# GPU0_KLIOMP1_HL_MMRS register map
Vendor: Texas Instruments
Peripheral module from a debugger description file (folder am65x).
Registers are 32-bit, access per field, reset values left out (the file's numbers can be read two ways) unless marked. A register's access mark holds for its fields unless they carry their own. Offsets are as the file gives them; lines under a group give offsets from that group; [hi:lo] are bit positions; {n}, {i} and the like mark numbered series; 'fields as' and 'values as' point back to an identical list; <NAME> marks a mode.

## GPU0_KLIOMP1_HL_MMRS
0x00 GPU_REVISION ro — See IPG spec for more details.
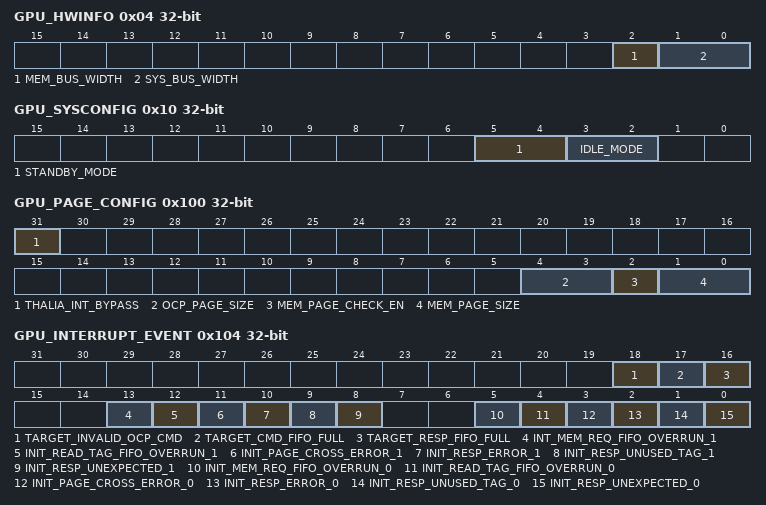
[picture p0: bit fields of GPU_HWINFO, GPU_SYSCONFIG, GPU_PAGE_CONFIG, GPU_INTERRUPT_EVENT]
0x04 GPU_HWINFO ro
  [2] MEM_BUS_WIDTH — Memory bus width Read 0h = 64 bits Read 1h = 128 bits
  [1:0] SYS_BUS_WIDTH — System bus width
0x10 GPU_SYSCONFIG
  [5:4] STANDBY_MODE rw — Clock standby mode:
  [3:2] IDLE_MODE rw — Clock idle mode:
0x24 GPU_IRQSTATUS_RAW_0
  [0] INIT_MINTERRUPT_RAW rw — Interrupt 0 raw event:
0x28 GPU_IRQSTATUS_RAW_1
  [0] TARGET_SINTERRUPT_RAW rw — Interrupt 1 raw event:
0x2C GPU_IRQSTATUS_RAW_2
  [0] THALIA_IRQ_RAW rw — Interrupt 1 raw event:
0x30 GPU_IRQSTATUS_0
  [0] INIT_MINTERRUPT_STATUS rw — Interrupt 0 raw event:
0x34 GPU_IRQSTATUS_1
  [0] TARGET_SINTERRUPT_STATUS rw — Interrupt 0 raw event:
0x38 GPU_IRQSTATUS_2
  [0] THALIA_IRQ_STATUS rw — Interrupt 0 raw event:
0x3C GPU_IRQENABLE_SET_0
  [0] INIT_MINTERRUPT_ENABLE rw — To enable interrupt:
0x40 GPU_IRQENABLE_SET_1
  [0] TARGET_SINTERRUPT_ENABLE rw — To enable interrupt:
0x44 GPU_IRQENABLE_SET_2
  [0] THALIA_IRQ_ENABLE rw — To enable interrupt:
0x48 GPU_IRQENABLE_CLR_0
  [0] INIT_MINTERRUPT_DISABLE rw — To disable interrupt:
0x4C GPU_IRQENABLE_CLR_1
  [0] TARGET_SINTERRUPT_DISABLE rw — To disable interrupt:
0x50 GPU_IRQENABLE_CLR_2
  [0] THALIA_IRQ_DISABLE rw — To disable interrupt:
0x100 GPU_PAGE_CONFIG
  [31] THALIA_INT_BYPASS rw — Bypass OCP IPG interrupt logic
  [4:3] OCP_PAGE_SIZE rw — Defines the page size on OCP memory interface:
  [2] MEM_PAGE_CHECK_EN rw — To enable page boundary checking:
  [1:0] MEM_PAGE_SIZE rw — Defines the page size on internal memory interface:
0x104 GPU_INTERRUPT_EVENT
  [18] TARGET_INVALID_OCP_CMD rw — Invalid command from OCP:
  [17] TARGET_CMD_FIFO_FULL rw — Command FIFO full:
  [16] TARGET_RESP_FIFO_FULL rw — Response FIFO full:
  [13] INT_MEM_REQ_FIFO_OVERRUN_1 rw — Memory request FIFO overrun:
  [12] INIT_READ_TAG_FIFO_OVERRUN_1 rw — Read tag FIFO overrun:
  [11] INIT_PAGE_CROSS_ERROR_1 rw — Memory page had been crossed during a burst:
  [10] INIT_RESP_ERROR_1 rw — Receiving error response:
  [9] INIT_RESP_UNUSED_TAG_1 rw — Receiving response on an unused OCP TAG:
  [8] INIT_RESP_UNEXPECTED_1 rw — Receiving response when not expected:
  [5] INIT_MEM_REQ_FIFO_OVERRUN_0 rw — Memory request FIFO overrun:
  [4] INIT_READ_TAG_FIFO_OVERRUN_0 rw — Read tag FIFO overrun:
  [3] INIT_PAGE_CROSS_ERROR_0 rw — Memory page had been crossed during a burst.
  [2] INIT_RESP_ERROR_0 rw — Receiving error response:
  [1] INIT_RESP_UNUSED_TAG_0 rw — Receiving response on an unused OCP TAG:
  [0] INIT_RESP_UNEXPECTED_0 rw — Receiving response when not expected:
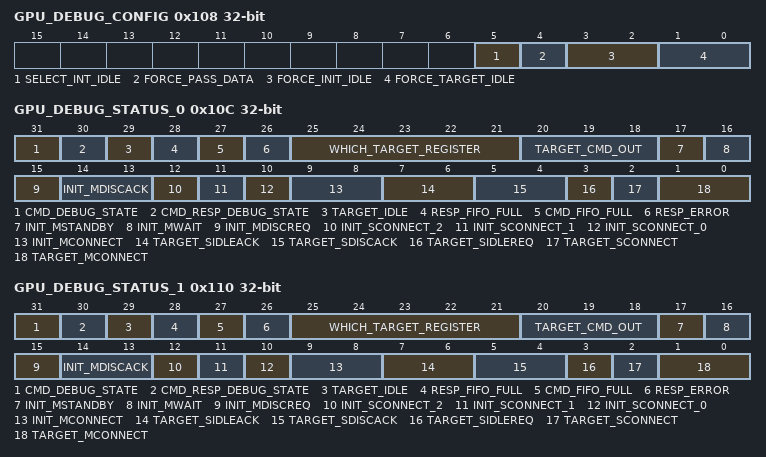
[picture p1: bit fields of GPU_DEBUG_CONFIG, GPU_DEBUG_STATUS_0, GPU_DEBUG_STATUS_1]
0x108 GPU_DEBUG_CONFIG
  [5] SELECT_INT_IDLE rw — To select which idle the disconnect protocol should act on:
  [4] FORCE_PASS_DATA rw — Forces the initiator to pass data independent of disconnect protocol:
  [3:2] FORCE_INIT_IDLE rw — Forces initiator idle:
  [1:0] FORCE_TARGET_IDLE rw — Forces target idle:
0x10C GPU_DEBUG_STATUS_0 ro — Port0 Debug Status Register
  [31] CMD_DEBUG_STATE — Target command state-machine:
  [30] CMD_RESP_DEBUG_STATE — Target response state-machine:
  [29] TARGET_IDLE
  [28] RESP_FIFO_FULL — Target response FIFO full
  [27] CMD_FIFO_FULL — Target command FIFO full
  [26] RESP_ERROR — Respond to OCP with error, which could be caused by either address misalignment or invalid byte enable.
  [25:21] WHICH_TARGET_REGISTER — Indicates which OCP target registers to read
  [20:18] TARGET_CMD_OUT — Command received from OCP:
  [17] INIT_MSTANDBY — Status of init_MStandby signal
  [16] INIT_MWAIT — Status of init_MWait signal
  [15] INIT_MDISCREQ — Request to disconnect from OCP interface
  [14:13] INIT_MDISCACK — Disconnect status of the OCP interface:
  [12] INIT_SCONNECT_2 — Defines whether to wait in M_WAIT state for MConnect FSM:
  [11] INIT_SCONNECT_1 — Defines the busy-ness state of the slave:
  [10] INIT_SCONNECT_0 — Disconnect from slave:
  [9:8] INIT_MCONNECT — Initiator MConnect state:
  [7:6] TARGET_SIDLEACK — Acknowledge the SIdleAck state-machine:
  [5:4] TARGET_SDISCACK — Acknowledge the SDiscAck state-machine:
  [3] TARGET_SIDLEREQ — Request the target to go idle:
  [2] TARGET_SCONNECT — Target SConnect bit 0 state:
  [1:0] TARGET_MCONNECT — Target MConnect state:
0x110 GPU_DEBUG_STATUS_1 ro — Port1 Debug Status Register
  fields as GPU_DEBUG_STATUS_0
